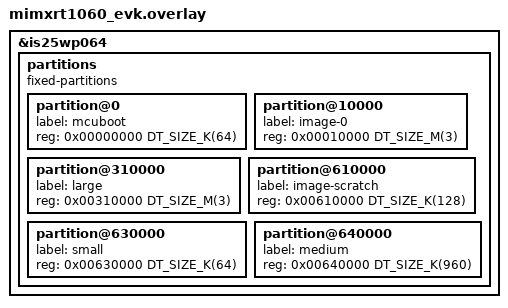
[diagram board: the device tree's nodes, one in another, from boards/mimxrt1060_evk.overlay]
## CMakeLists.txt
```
# SPDX-License-Identifier: Apache-2.0

cmake_minimum_required(VERSION 3.13.1)
find_package(Zephyr REQUIRED HINTS $ENV{ZEPHYR_BASE})
project(littlefs)

FILE(GLOB app_sources src/*.c)
# LittleFS opens files for RW by default if no flags given and crashes,
# instead of returning error when attempting to perform operation that
# a file has not been opened for.
target_compile_definitions(app PRIVATE
		BYPASS_FS_OPEN_FLAGS_LFS_ASSERT_CRASH
		BYPASS_FS_OPEN_FLAGS_LFS_RW_IS_DEFAULT
)
target_sources(app PRIVATE ${app_sources} ../common/test_fs_open_flags.c)
```

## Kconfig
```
# SPDX-License-Identifier: Apache-2.0
# Copyright (c) 2020 Nordic Semicondutor ASA

mainmenu "littlefs core functionality test"

source "Kconfig.zephyr"

config APP_TEST_CUSTOM
	bool "Select to test additional custom filesystem configurations"
```

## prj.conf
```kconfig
CONFIG_FILE_SYSTEM=y
CONFIG_FILE_SYSTEM_LITTLEFS=y

CONFIG_MAIN_STACK_SIZE=4096

# Performance tests need custom buffer allocation
CONFIG_MINIMAL_LIBC_MALLOC_ARENA_SIZE=8192

# FS abstraction layer is noisy so it's off.  Turn it on to see the
# littlefs configuration parameters.
#CONFIG_LOG=y
#CONFIG_FS_LOG_LEVEL_DBG=y

CONFIG_FLASH=y
CONFIG_FLASH_MAP=y
CONFIG_FLASH_PAGE_LAYOUT=y

CONFIG_ZTEST=y
CONFIG_ZTEST_STACKSIZE=4096
```

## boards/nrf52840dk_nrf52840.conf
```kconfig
#
# Copyright (c) 2019 Peter Bigot Consulting, LLC
# Copyright (c) 2019 Nordic Semiconductor ASA
#
# SPDX-License-Identifier: Apache-2.0
#

CONFIG_NORDIC_QSPI_NOR=y
CONFIG_NORDIC_QSPI_NOR_FLASH_LAYOUT_PAGE_SIZE=4096
```

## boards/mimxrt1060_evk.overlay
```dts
/*
 * Copyright (c) 2021 NXP
 *
 * SPDX-License-Identifier: Apache-2.0
 */

&is25wp064 {
	partitions {
		compatible = "fixed-partitions";
		#address-cells = <1>;
		#size-cells = <1>;

		partition@0 {
			label = "mcuboot";
			reg = <0x00000000 DT_SIZE_K(64)>;
		};
		partition@10000 {
			label = "image-0";
			reg = <0x00010000 DT_SIZE_M(3)>;
		};
		partition@310000 {
			label = "large";
			reg = <0x00310000 DT_SIZE_M(3)>;
		};
		partition@610000 {
			label = "image-scratch";
			reg = <0x00610000 DT_SIZE_K(128)>;
		};
		partition@630000 {
			label = "small";
			reg = <0x00630000 DT_SIZE_K(64)>;
		};
		partition@640000 {
			label = "medium";
			reg = <0x00640000 DT_SIZE_K(960)>;
		};
	};
};
```

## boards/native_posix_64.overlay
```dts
/*
 * Copyright (c) 2019 Jan Van Winkel <jan.van_winkel@dxplore.eu>
 *
 * SPDX-License-Identifier: Apache-2.0
 */

&flashcontroller0 {
	reg = <0x00000000 DT_SIZE_K(4096)>;
};

&flash0 {
	reg = <0x00000000 DT_SIZE_K(4096)>;
	partitions {
		compatible = "fixed-partitions";
		#address-cells = <1>;
		#size-cells = <1>;

		partition@0 {
			label = "small";
			reg = <0x00000000 0x00010000>;
		};
		partition@10000 {
			label = "medium";
			reg = <0x00010000 0x000F0000>;
		};
		partition@100000 {
			label = "large";
			reg = <0x00100000 0x00300000>;
		};
	};
};
```

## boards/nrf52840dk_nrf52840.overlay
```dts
/*
 * Copyright (c) 2019 Peter Bigot Consulting, LLC
 *
 * SPDX-License-Identifier: Apache-2.0
 */

&mx25r64 {
	partitions {
		compatible = "fixed-partitions";
		#address-cells = <1>;
		#size-cells = <1>;

 		partition@0 {
			label = "small";
			reg = <0x00000000 0x00010000>;
		};
		partition@10000 {
			label = "medium";
			reg = <0x00010000 0x000F0000>;
		};
		partition@100000 {
			label = "large";
			reg = <0x00100000 0x00300000>;
		};
	};
};
```

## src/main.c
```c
/*
 * Copyright (c) 2019 Peter Bigot Consulting, LLC
 *
 * SPDX-License-Identifier: Apache-2.0
 */

/* Tests of functions in testfs_util */

#include <string.h>
#include <ztest.h>
#include "testfs_tests.h"
#include "testfs_lfs.h"

void test_main(void)
{
	ztest_test_suite(littlefs_test,
			 ztest_unit_test(test_util_path_init_base),
			 ztest_unit_test(test_util_path_init_overrun),
			 ztest_unit_test(test_util_path_init_extended),
			 ztest_unit_test(test_util_path_extend),
			 ztest_unit_test(test_util_path_extend_up),
			 ztest_unit_test(test_util_path_extend_overrun),
			 ztest_unit_test(test_lfs_basic),
			 ztest_unit_test(test_lfs_dirops),
			 ztest_unit_test(test_lfs_perf),
			 ztest_unit_test(test_fs_open_flags_lfs),
			 ztest_unit_test(test_fs_mount_flags)
			 );
	ztest_run_test_suite(littlefs_test);
}
```

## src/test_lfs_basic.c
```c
/*
 * Copyright (c) 2019 Peter Bigot Consulting, LLC
 *
 * SPDX-License-Identifier: Apache-2.0
 */

/* Basic littlefs operations:
 * * create
 * * write
 * * stat
 * * read
 * * seek
 * * tell
 * * truncate
 * * unlink
 * * sync
 */

#include <string.h>
#include <ztest.h>
#include "testfs_tests.h"
#include "testfs_lfs.h"
#include <lfs.h>

#include <fs/littlefs.h>

#define HELLO "hello"
#define GOODBYE "goodbye"

static int mount(struct fs_mount_t *mp)
{
	TC_PRINT("mounting %s\n", mp->mnt_point);

	zassert_equal(fs_mount(mp), 0,
		      "mount failed");

	return TC_PASS;
}

static int clear_partition(struct fs_mount_t *mp)
{
	TC_PRINT("clearing partition %s\n", mp->mnt_point);

	zassert_equal(testfs_lfs_wipe_partition(mp),
		      TC_PASS,
		      "failed to wipe partition");

	return TC_PASS;
}

static int clean_statvfs(const struct fs_mount_t *mp)
{
	struct fs_statvfs stat;

	TC_PRINT("checking clean statvfs of %s\n", mp->mnt_point);

	zassert_equal(fs_statvfs(mp->mnt_point, &stat), 0,
		      "statvfs failed");

	TC_PRINT("%s: bsize %lu ; frsize %lu ; blocks %lu ; bfree %lu\n",
		 mp->mnt_point,
		 stat.f_bsize, stat.f_frsize, stat.f_blocks, stat.f_bfree);
	zassert_equal(stat.f_bsize, 16,
		      "bsize fail");
	zassert_equal(stat.f_frsize, 4096,
		      "frsize fail");
	zassert_equal(stat.f_blocks, 16,
		      "blocks fail");
	zassert_equal(stat.f_bfree, stat.f_blocks - 2U,
		      "bfree fail");

	return TC_PASS;
}

static int create_write_hello(const struct fs_mount_t *mp)
{
	struct testfs_path path;
	struct fs_file_t file;

	fs_file_t_init(&file);
	TC_PRINT("creating and writing file\n");

	zassert_equal(fs_open(&file,
			      testfs_path_init(&path, mp,
					       HELLO,
					       TESTFS_PATH_END),
			      FS_O_CREATE | FS_O_RDWR),
		      0,
		      "open hello failed");

	struct fs_dirent stat;

	zassert_equal(fs_stat(path.path, &stat),
		      0,
		      "stat new hello failed");

	zassert_equal(stat.type, FS_DIR_ENTRY_FILE,
		      "stat new hello not file");
	zassert_equal(strcmp(stat.name, HELLO), 0,
		      "stat new hello not hello");
	zassert_equal(stat.size, 0,
		      "stat new hello not empty");

	zassert_equal(testfs_write_incrementing(&file, 0, TESTFS_BUFFER_SIZE),
		      TESTFS_BUFFER_SIZE,
		      "write constant failed");

	zassert_equal(fs_stat(path.path, &stat),
		      0,
		      "stat written hello failed");

	zassert_equal(stat.type, FS_DIR_ENTRY_FILE,
		      "stat written hello not file");
	zassert_equal(strcmp(stat.name, HELLO), 0,
		      "stat written hello not hello");

	/* Anomalous behavior requiring upstream response */
	if (true) {
		/* VARIATION POINT: littlefs does not update the file size of
		 * an open file.  See upstream issue #250.
		 */
		zassert_equal(stat.size, 0,
			      "stat written hello bad size");
	}

	zassert_equal(fs_close(&file), 0,
		      "close hello failed");

	zassert_equal(fs_stat(path.path, &stat),
		      0,
		      "stat closed hello failed");

	zassert_equal(stat.type, FS_DIR_ENTRY_FILE,
		      "stat closed hello not file");
	zassert_equal(strcmp(stat.name, HELLO), 0,
		      "stat closed hello not hello");
	zassert_equal(stat.size, TESTFS_BUFFER_SIZE,
		      "stat closed hello badsize");

	return TC_PASS;
}

static int verify_hello(const struct fs_mount_t *mp)
{
	struct testfs_path path;
	struct fs_file_t file;

	fs_file_t_init(&file);
	TC_PRINT("opening and verifying file\n");

	zassert_equal(fs_open(&file,
			      testfs_path_init(&path, mp,
					       HELLO,
					       TESTFS_PATH_END),
			      FS_O_CREATE | FS_O_RDWR),
		      0,
		      "verify hello open failed");

	zassert_equal(fs_tell(&file), 0U,
		      "verify hello open tell failed");

	zassert_equal(testfs_verify_incrementing(&file, 0, TESTFS_BUFFER_SIZE),
		      TESTFS_BUFFER_SIZE,
		      "verify hello at start failed");

	zassert_equal(fs_tell(&file), TESTFS_BUFFER_SIZE,
		      "verify hello read tell failed");

	zassert_equal(fs_close(&file), 0,
		      "verify close hello failed");

	return TC_PASS;
}

static int seek_within_hello(const struct fs_mount_t *mp)
{
	struct testfs_path path;
	struct fs_file_t file;

	fs_file_t_init(&file);
	TC_PRINT("seek and tell in file\n");

	zassert_equal(fs_open(&file,
			      testfs_path_init(&path, mp,
					       HELLO,
					       TESTFS_PATH_END),
			      FS_O_CREATE | FS_O_RDWR),
		      0,
		      "verify hello open failed");

	zassert_equal(fs_tell(&file), 0U,
		      "verify hello open tell failed");

	struct fs_dirent stat;

	zassert_equal(fs_stat(path.path, &stat),
		      0,
		      "stat old hello failed");
	zassert_equal(stat.size, TESTFS_BUFFER_SIZE,
		      "stat old hello bad size");

	off_t pos = stat.size / 4;

	zassert_equal(fs_seek(&file, pos, FS_SEEK_SET),
		      0,
		      "verify hello seek near mid failed");

	zassert_equal(fs_tell(&file), pos,
		      "verify hello tell near mid failed");

	zassert_equal(testfs_verify_incrementing(&file, pos, TESTFS_BUFFER_SIZE),
		      TESTFS_BUFFER_SIZE - pos,
		      "verify hello at middle failed");

	zassert_equal(fs_tell(&file), stat.size,
		      "verify hello read middle tell failed");

	zassert_equal(fs_seek(&file, -stat.size, FS_SEEK_CUR),
		      0,
		      "verify hello seek back from cur failed");

	zassert_equal(fs_tell(&file), 0U,
		      "verify hello tell back from cur failed");

	zassert_equal(fs_seek(&file, -pos, FS_SEEK_END),
		      0,
		      "verify hello seek from end failed");

	zassert_equal(fs_tell(&file), stat.size - pos,
		      "verify hello tell from end failed");

	zassert_equal(testfs_verify_incrementing(&file, stat.size - pos,
						 TESTFS_BUFFER_SIZE),
		      pos,
		      "verify hello at post middle failed");

	zassert_equal(fs_close(&file), 0,
		      "verify close hello failed");

	return TC_PASS;
}

static int truncate_hello(const struct fs_mount_t *mp)
{
	struct testfs_path path;
	struct fs_file_t file;

	fs_file_t_init(&file);
	TC_PRINT("truncate in file\n");

	zassert_equal(fs_open(&file,
			      testfs_path_init(&path, mp,
					       HELLO,
					       TESTFS_PATH_END),
			      FS_O_CREATE | FS_O_RDWR),
		      0,
		      "verify hello open failed");

	struct fs_dirent stat;

	zassert_equal(fs_stat(path.path, &stat),
		      0,
		      "stat old hello failed");
	zassert_equal(stat.size, TESTFS_BUFFER_SIZE,
		      "stat old hello bad size");

	off_t pos = 3 * stat.size / 4;

	zassert_equal(fs_tell(&file), 0U,
		      "truncate initial tell failed");

	zassert_equal(fs_truncate(&file, pos),
		      0,
		      "truncate 3/4 failed");

	zassert_equal(fs_tell(&file), 0U,
		      "truncate post tell failed");

	zassert_equal(fs_stat(path.path, &stat),
		      0,
		      "stat open 3/4 failed");

	/* Anomalous behavior requiring upstream response */
	if (true) {
		/* VARIATION POINT: littlefs does not update the file size of
		 * an open file.  See upstream issue #250.
		 */
		zassert_equal(stat.size, TESTFS_BUFFER_SIZE,
			      "stat open 3/4 bad size");
	}

	zassert_equal(testfs_verify_incrementing(&file, 0, 64),
		      48,
		      "post truncate content unexpected");

	zassert_equal(fs_close(&file), 0,
		      "post truncate close failed");

	/* After close size is correct. */
	zassert_equal(fs_stat(path.path, &stat),
		      0,
		      "stat closed truncated failed");
	zassert_equal(stat.size, pos,
		      "stat closed truncated bad size");

	return TC_PASS;
}

static int unlink_hello(const struct fs_mount_t *mp)
{
	struct testfs_path path;

	TC_PRINT("unlink hello\n");

	testfs_path_init(&path, mp,
			 HELLO,
			 TESTFS_PATH_END);

	struct fs_dirent stat;

	zassert_equal(fs_stat(path.path, &stat),
		      0,
		      "stat existing hello failed");
	zassert_equal(fs_unlink(path.path),
		      0,
		      "unlink hello failed");
	zassert_equal(fs_stat(path.path, &stat),
		      -ENOENT,
		      "stat existing hello failed");

	return TC_PASS;
}

static int sync_goodbye(const struct fs_mount_t *mp)
{
	struct testfs_path path;
	struct fs_file_t file;

	fs_file_t_init(&file);
	TC_PRINT("sync goodbye\n");

	zassert_equal(fs_open(&file,
			      testfs_path_init(&path, mp,
					       GOODBYE,
					       TESTFS_PATH_END),
			      FS_O_CREATE | FS_O_RDWR),
		      0,
		      "sync goodbye failed");

	struct fs_dirent stat;

	zassert_equal(fs_stat(path.path, &stat),
		      0,
		      "stat existing hello failed");
	zassert_equal(stat.size, 0,
		      "stat new goodbye not empty");

	zassert_equal(testfs_write_incrementing(&file, 0, TESTFS_BUFFER_SIZE),
		      TESTFS_BUFFER_SIZE,
		      "write goodbye failed");

	zassert_equal(fs_tell(&file), TESTFS_BUFFER_SIZE,
		      "tell goodbye failed");

	if (true) {
		/* Upstream issue #250 */
		zassert_equal(stat.size, 0,
			      "stat new goodbye not empty");
	}

	zassert_equal(fs_sync(&file), 0,
		      "sync goodbye failed");

	zassert_equal(fs_tell(&file), TESTFS_BUFFER_SIZE,
		      "tell synced moved");

	zassert_equal(fs_stat(path.path, &stat),
		      0,
		      "stat existing hello failed");
	printk("sync size %u\n", (uint32_t)stat.size);

	zassert_equal(stat.size, TESTFS_BUFFER_SIZE,
		      "stat synced goodbye not correct");

	zassert_equal(fs_close(&file), 0,
		      "post sync close failed");

	/* After close size is correct. */
	zassert_equal(fs_stat(path.path, &stat),
		      0,
		      "stat sync failed");
	zassert_equal(stat.size, TESTFS_BUFFER_SIZE,
		      "stat sync bad size");

	return TC_PASS;
}

static int verify_goodbye(const struct fs_mount_t *mp)
{
	struct testfs_path path;
	struct fs_file_t file;

	fs_file_t_init(&file);
	TC_PRINT("verify goodbye\n");

	zassert_equal(fs_open(&file,
			      testfs_path_init(&path, mp,
					       GOODBYE,
					       TESTFS_PATH_END),
			      FS_O_CREATE | FS_O_RDWR),
		      0,
		      "verify goodbye failed");

	zassert_equal(testfs_verify_incrementing(&file, 0, TESTFS_BUFFER_SIZE),
		      TESTFS_BUFFER_SIZE,
		      "write goodbye failed");

	zassert_equal(fs_close(&file), 0,
		      "post sync close failed");

	return TC_PASS;
}

static int check_medium(void)
{
	struct fs_mount_t *mp = &testfs_medium_mnt;
	struct fs_statvfs stat;

	zassert_equal(clear_partition(mp), TC_PASS,
		      "clear partition failed");

	zassert_equal(fs_mount(mp), 0,
		      "medium mount failed");

	zassert_equal(fs_statvfs(mp->mnt_point, &stat), 0,
		      "statvfs failed");

	TC_PRINT("%s: bsize %lu ; frsize %lu ; blocks %lu ; bfree %lu\n",
		 mp->mnt_point,
		 stat.f_bsize, stat.f_frsize, stat.f_blocks, stat.f_bfree);
	zassert_equal(stat.f_bsize, MEDIUM_IO_SIZE,
		      "bsize fail");
	zassert_equal(stat.f_frsize, 4096,
		      "frsize fail");
	zassert_equal(stat.f_blocks, 240,
		      "blocks fail");
	zassert_equal(stat.f_bfree, stat.f_blocks - 2U,
		      "bfree fail");

	zassert_equal(fs_unmount(mp), 0,
		      "medium unmount failed");

	return TC_PASS;
}

static int check_large(void)
{
	struct fs_mount_t *mp = &testfs_large_mnt;
	struct fs_statvfs stat;

	zassert_equal(clear_partition(mp), TC_PASS,
		      "clear partition failed");

	zassert_equal(fs_mount(mp), 0,
		      "large mount failed");

	zassert_equal(fs_statvfs(mp->mnt_point, &stat), 0,
		      "statvfs failed");

	TC_PRINT("%s: bsize %lu ; frsize %lu ; blocks %lu ; bfree %lu\n",
		 mp->mnt_point,
		 stat.f_bsize, stat.f_frsize, stat.f_blocks, stat.f_bfree);
	zassert_equal(stat.f_bsize, LARGE_IO_SIZE,
		      "bsize fail");
	zassert_equal(stat.f_frsize, 32768,
		      "frsize fail");
	zassert_equal(stat.f_blocks, 96,
		      "blocks fail");
	zassert_equal(stat.f_bfree, stat.f_blocks - 2U,
		      "bfree fail");

	zassert_equal(fs_unmount(mp), 0,
		      "large unmount failed");

	return TC_PASS;
}

static int num_files(struct fs_mount_t *mp)
{
	struct testfs_path path;
	char name[2] = { 0 };
	const char *pstr;
	struct fs_file_t files[CONFIG_FS_LITTLEFS_NUM_FILES];
	size_t fi = 0;
	int rc;

	memset(files, 0, sizeof(files));

	TC_PRINT("CONFIG_FS_LITTLEFS_NUM_FILES=%u\n", CONFIG_FS_LITTLEFS_NUM_FILES);
	while (fi < ARRAY_SIZE(files)) {
		struct fs_file_t *const file = &files[fi];

		name[0] = 'A' + fi;
		pstr = testfs_path_init(&path, mp,
					name,
					TESTFS_PATH_END);

		TC_PRINT("opening %s\n", pstr);
		rc = fs_open(file, pstr, FS_O_CREATE | FS_O_RDWR);
		zassert_equal(rc, 0, "open %s failed: %d", pstr, rc);

		rc = testfs_write_incrementing(file, 0, TESTFS_BUFFER_SIZE);
		zassert_equal(rc, TESTFS_BUFFER_SIZE, "write %s failed: %d", pstr, rc);

		++fi;
	}

	while (fi-- != 0)  {
		struct fs_file_t *const file = &files[fi];

		name[0] = 'A' + fi;
		pstr = testfs_path_init(&path, mp,
					name,
					TESTFS_PATH_END);

		TC_PRINT("Close and unlink %s\n", pstr);

		rc = fs_close(file);
		zassert_equal(rc, 0, "close %s failed: %d", pstr, rc);

		rc = fs_unlink(pstr);
		zassert_equal(rc, 0, "unlink %s failed: %d", pstr, rc);
	}

	return TC_PASS;
}

static int num_dirs(struct fs_mount_t *mp)
{
	struct testfs_path path;
	char name[3] = "Dx";
	const char *pstr;
	struct fs_dir_t dirs[CONFIG_FS_LITTLEFS_NUM_DIRS];
	size_t di = 0;
	int rc;

	memset(dirs, 0, sizeof(dirs));

	TC_PRINT("CONFIG_FS_LITTLEFS_NUM_DIRS=%u\n", CONFIG_FS_LITTLEFS_NUM_DIRS);
	while (di < ARRAY_SIZE(dirs)) {
		struct fs_dir_t *const dir = &dirs[di];

		name[1] = 'A' + di;
		pstr = testfs_path_init(&path, mp,
					name,
					TESTFS_PATH_END);

		TC_PRINT("making and opening directory %s\n", pstr);
		rc = fs_mkdir(pstr);
		zassert_equal(rc, 0, "mkdir %s failed: %d", pstr, rc);

		rc = fs_opendir(dir, pstr);
		zassert_equal(rc, 0, "opendir %s failed: %d", name, rc);

		++di;
	}

	while (di-- != 0)  {
		struct fs_dir_t *const dir = &dirs[di];

		name[1] = 'A' + di;
		pstr = testfs_path_init(&path, mp,
					name,
					TESTFS_PATH_END);

		TC_PRINT("Close and rmdir %s\n", pstr);

		rc = fs_closedir(dir);
		zassert_equal(rc, 0, "closedir %s failed: %d", name, rc);

		rc = fs_unlink(pstr);
		zassert_equal(rc, 0, "unlink %s failed: %d", name, rc);
	}

	return TC_PASS;
}

void test_lfs_basic(void)
{
	struct fs_mount_t *mp = &testfs_small_mnt;

	zassert_equal(clear_partition(mp), TC_PASS,
		      "clear partition failed");

	zassert_equal(mount(mp), TC_PASS,
		      "clean mount failed");

	zassert_equal(clean_statvfs(mp), TC_PASS,
		      "clean statvfs failed");

	zassert_equal(create_write_hello(mp), TC_PASS,
		      "write hello failed");

	zassert_equal(verify_hello(mp), TC_PASS,
		      "verify hello failed");

	zassert_equal(seek_within_hello(mp), TC_PASS,
		      "seek within hello failed");

	zassert_equal(truncate_hello(mp), TC_PASS,
		      "truncate hello failed");

	zassert_equal(unlink_hello(mp), TC_PASS,
		      "unlink hello failed");

	zassert_equal(sync_goodbye(mp), TC_PASS,
		      "sync goodbye failed");

	zassert_equal(num_files(mp), TC_PASS,
		      "num_files failed");

	zassert_equal(num_dirs(mp), TC_PASS,
		      "num_dirs failed");

	TC_PRINT("unmounting %s\n", mp->mnt_point);
	zassert_equal(fs_unmount(mp), 0,
		      "unmount small failed");

	k_sleep(K_MSEC(100));   /* flush log messages */
	TC_PRINT("checking double unmount diagnoses\n");
	zassert_equal(fs_unmount(mp), -EINVAL,
		      "unmount unmounted failed");

	zassert_equal(mount(mp), TC_PASS,
		      "remount failed");

	zassert_equal(verify_goodbye(mp), TC_PASS,
		      "verify goodbye failed");

	zassert_equal(fs_unmount(mp), 0,
		      "unmount2 small failed");

	if (IS_ENABLED(CONFIG_APP_TEST_CUSTOM)) {
		zassert_equal(check_medium(), TC_PASS,
			      "check medium failed");

		zassert_equal(check_large(), TC_PASS,
			      "check large failed");
	}
}
```

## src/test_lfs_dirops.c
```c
/*
 * Copyright (c) 2019 Peter Bigot Consulting, LLC
 *
 * SPDX-License-Identifier: Apache-2.0
 */

/* Director littlefs operations:
 * * mkdir
 * * opendir
 * * readdir
 * * closedir
 * * rename
 */

#include <string.h>
#include <ztest.h>
#include "testfs_tests.h"
#include "testfs_lfs.h"
#include <lfs.h>

#include <fs/littlefs.h>

static struct testfs_bcmd test_hierarchy[] = {
	TESTFS_BCMD_FILE("f1", 1, 1),
	TESTFS_BCMD_FILE("f2", 2, 100),
	TESTFS_BCMD_ENTER_DIR("d1"),
	TESTFS_BCMD_FILE("d1f1", 11, 23),
	TESTFS_BCMD_FILE("d1f2", 12, 612),
	TESTFS_BCMD_EXIT_DIR(),
	TESTFS_BCMD_FILE("f3", 3, 10000),
	TESTFS_BCMD_END(),
};

static int clean_mount(struct fs_mount_t *mp)
{
	TC_PRINT("checking clean mount\n");

	zassert_equal(testfs_lfs_wipe_partition(mp),
		      TC_PASS,
		      "failed to wipe partition");
	zassert_equal(fs_mount(mp), 0,
		      "mount small failed");

	return TC_PASS;
}

static int check_mkdir(struct fs_mount_t *mp)
{
	struct testfs_path dpath;

	TC_PRINT("checking dir create unlink\n");
	zassert_equal(testfs_path_init(&dpath, mp,
				       "dir",
				       TESTFS_PATH_END),
		      dpath.path,
		      "root init failed");

	zassert_equal(fs_mkdir(dpath.path),
		      0,
		      "mkdir failed");

	struct fs_file_t file;
	struct testfs_path fpath;

	fs_file_t_init(&file);
	zassert_equal(fs_open(&file,
			      testfs_path_extend(testfs_path_copy(&fpath,
								  &dpath),
						 "file",
						 TESTFS_PATH_END),
			      FS_O_CREATE | FS_O_RDWR),
		      0,
		      "creat in dir failed");
	zassert_equal(fs_close(&file), 0,
		      "close file failed");

	struct fs_dirent stat;

	zassert_equal(fs_stat(fpath.path, &stat), 0,
		      "stat file failed");

	zassert_equal(fs_unlink(dpath.path),
		      -ENOTEMPTY,
		      "unlink bad failure");

	zassert_equal(fs_unlink(fpath.path),
		      0,
		      "unlink file failed");

	zassert_equal(fs_unlink(dpath.path),
		      0,
		      "unlink dir failed");

	return TC_PASS;
}

static int build_layout(struct fs_mount_t *mp,
			const struct testfs_bcmd *cp)
{
	struct testfs_path path;
	struct fs_statvfs stat;

	TC_PRINT("building layout on %s\n", mp->mnt_point);

	zassert_equal(fs_statvfs(mp->mnt_point, &stat), 0,
		      "statvfs failed");

	TC_PRINT("before: bsize %lu ; frsize %lu ; blocks %lu ; bfree %lu\n",
		 stat.f_bsize, stat.f_frsize, stat.f_blocks, stat.f_bfree);

	zassert_equal(testfs_path_init(&path, mp, TESTFS_PATH_END),
		      path.path,
		      "root init failed");

	zassert_equal(testfs_build(&path, cp),
		      0,
		      "build_layout failed");

	zassert_equal(fs_statvfs(mp->mnt_point, &stat), 0,
		      "statvfs failed");

	TC_PRINT("after: bsize %lu ; frsize %lu ; blocks %lu ; bfree %lu\n",
		 stat.f_bsize, stat.f_frsize, stat.f_blocks, stat.f_bfree);

	return TC_PASS;
}

static int check_layout(struct fs_mount_t *mp,
			struct testfs_bcmd *layout)
{
	struct testfs_path path;
	struct testfs_bcmd *end_layout = testfs_bcmd_end(layout);

	TC_PRINT("checking layout\n");

	zassert_equal(testfs_path_init(&path, mp, TESTFS_PATH_END),
		      path.path,
		      "root init failed");

	int rc = testfs_bcmd_verify_layout(&path, layout, end_layout);

	zassert_true(rc >= 0, "layout check failed");

	zassert_equal(rc, 0,
		      "layout found foreign");

	struct testfs_bcmd *cp = layout;

	while (!TESTFS_BCMD_IS_END(cp)) {
		if (cp->name != NULL) {
			TC_PRINT("verifying %s%s %u\n",
				 cp->name,
				 (cp->type == FS_DIR_ENTRY_DIR) ? "/" : "",
				 cp->size);
			zassert_true(cp->matched,
				     "Unmatched layout entry");
		}
		++cp;
	}

	return TC_PASS;
}

static int check_rename(struct fs_mount_t *mp)
{
	struct testfs_path root;
	struct testfs_path from_path;
	const char *from = from_path.path;
	struct testfs_path to_path;
	const char *to = to_path.path;
	struct fs_dirent stat;
	struct testfs_bcmd from_bcmd[] = {
		TESTFS_BCMD_FILE("f1f", 1, 8),  /* from f1f to f1t */
		TESTFS_BCMD_FILE("f2f", 2, 8),  /* from f2f to f2t */
		TESTFS_BCMD_FILE("f2t", 3, 8),  /* target for f2f clobber, replaced */
		TESTFS_BCMD_FILE("f3f", 4, 8),  /* from f3f to d1f/d1f2t */
		TESTFS_BCMD_FILE("f4f", 5, 8),  /* from f4f to d2t, reject */
		TESTFS_BCMD_ENTER_DIR("d1f"),   /* from d1f to d1t */
		TESTFS_BCMD_FILE("d1f1", 5, 16),
		TESTFS_BCMD_EXIT_DIR(),
		TESTFS_BCMD_ENTER_DIR("d2t"),  /* target for d1f, unchanged */
		TESTFS_BCMD_FILE("d2f1", 6, 16),
		TESTFS_BCMD_EXIT_DIR(),
		TESTFS_BCMD_END(),
	};
	struct testfs_bcmd *from_end_bcmd = testfs_bcmd_end(from_bcmd);
	struct testfs_bcmd to_bcmd[] = {
		TESTFS_BCMD_FILE("f1t", 1, 8),          /* from f1f to f1t */
		TESTFS_BCMD_FILE("f2t", 2, 8),          /* from f2f to f2t */
		TESTFS_BCMD_FILE("f4f", 5, 8),          /* from f4f to d2t, reject */
		TESTFS_BCMD_ENTER_DIR("d1t"),           /* from d1f to d1t */
		TESTFS_BCMD_FILE("d1f1", 5, 16),
		TESTFS_BCMD_FILE("d1f2t", 4, 8),        /* from f3f to d1f/d1f2t */
		TESTFS_BCMD_EXIT_DIR(),
		TESTFS_BCMD_ENTER_DIR("d2t"),           /* target for d1f, unchanged */
		TESTFS_BCMD_FILE("d2f1", 6, 16),
		TESTFS_BCMD_EXIT_DIR(),
		TESTFS_BCMD_END(),
	};
	struct testfs_bcmd *to_end_bcmd = testfs_bcmd_end(to_bcmd);

	zassert_equal(testfs_path_init(&root, mp,
				       "rename",
				       TESTFS_PATH_END),
		      root.path,
		      "root init failed");

	zassert_equal(fs_mkdir(root.path),
		      0,
		      "rename mkdir failed");
	zassert_equal(testfs_build(&root, from_bcmd),
		      0,
		      "rename build failed");

	zassert_equal(testfs_bcmd_verify_layout(&root, from_bcmd, from_end_bcmd),
		      0,
		      "layout check failed");

	testfs_path_extend(testfs_path_copy(&from_path, &root),
			   "nofile",
			   TESTFS_PATH_END);
	testfs_path_extend(testfs_path_copy(&to_path, &root),
			   "f1t",
			   TESTFS_PATH_END);
	TC_PRINT("%s => %s -ENOENT\n", from, to);
	zassert_equal(fs_rename(from, to),
		      -ENOENT,
		      "rename noent failed");

	/* f1f => f1t : ok */
	testfs_path_extend(testfs_path_copy(&from_path, &root),
			   "f1f",
			   TESTFS_PATH_END);
	TC_PRINT("%s => %s ok\n", from, to);
	zassert_equal(fs_rename(from, to),
		      0,
		      "rename noent failed");

	/* f2f => f2t : clobbers */
	testfs_path_extend(testfs_path_copy(&from_path, &root),
			   "f2f",
			   TESTFS_PATH_END);
	testfs_path_extend(testfs_path_copy(&to_path, &root),
			   "f2t",
			   TESTFS_PATH_END);
	TC_PRINT("%s => %s clobber ok\n", from, to);
	zassert_equal(fs_rename(from, to),
		      0,
		      "rename clobber failed");
	zassert_equal(fs_stat(from, &stat),
		      -ENOENT,
		      "rename clobber left from");

	/* f3f => d1f/d1f2t : moves */
	testfs_path_extend(testfs_path_copy(&from_path, &root),
			   "f3f",
			   TESTFS_PATH_END);
	testfs_path_extend(testfs_path_copy(&to_path, &root),
			   "d1f", "d1f2t",
			   TESTFS_PATH_END);
	TC_PRINT("%s => %s move ok\n", from, to);
	zassert_equal(fs_rename(from, to),
		      0,
		      "rename to subdir failed");
	zassert_equal(fs_stat(from, &stat),
		      -ENOENT,
		      "rename to subdir left from");

	/* d1f => d2t : reject */
	testfs_path_extend(testfs_path_copy(&from_path, &root),
			   "d1f",
			   TESTFS_PATH_END);
	testfs_path_extend(testfs_path_copy(&to_path, &root),
			   "d2t",
			   TESTFS_PATH_END);
	TC_PRINT("%s => %s -ENOTEMPTY\n", from, to);
	zassert_equal(fs_rename(from, to),
		      -ENOTEMPTY,
		      "rename to existing dir failed");

	/* d1f => d1t : rename */
	testfs_path_extend(testfs_path_copy(&from_path, &root),
			   "d1f",
			   TESTFS_PATH_END);
	testfs_path_extend(testfs_path_copy(&to_path, &root),
			   "d1t",
			   TESTFS_PATH_END);
	TC_PRINT("%s => %s ok\n", from, to);
	zassert_equal(fs_rename(from, to),
		      0,
		      "rename to new dir failed");
	zassert_equal(fs_stat(from, &stat),
		      -ENOENT,
		      "rename to new dir left from");

	zassert_equal(testfs_bcmd_verify_layout(&root, to_bcmd, to_end_bcmd),
		      0,
		      "layout verification failed");

	struct testfs_bcmd *cp = to_bcmd;

	while (cp != to_end_bcmd) {
		if (cp->name) {
			zassert_true(cp->matched, "foriegn file retained");
		}
		++cp;
	}

	return TC_PASS;
}

void test_lfs_dirops(void)
{
	struct fs_mount_t *mp = &testfs_small_mnt;

	zassert_equal(clean_mount(mp), TC_PASS,
		      "clean mount failed");

	zassert_equal(check_mkdir(mp), TC_PASS,
		      "check mkdir failed");

	k_sleep(K_MSEC(100));   /* flush log messages */
	zassert_equal(build_layout(mp, test_hierarchy), TC_PASS,
		      "build test hierarchy failed");

	k_sleep(K_MSEC(100));   /* flush log messages */
	zassert_equal(check_layout(mp, test_hierarchy), TC_PASS,
		      "check test hierarchy failed");

	k_sleep(K_MSEC(100));   /* flush log messages */
	zassert_equal(check_rename(mp), TC_PASS,
		      "check rename failed");

	k_sleep(K_MSEC(100));   /* flush log messages */
	zassert_equal(fs_unmount(mp), 0,
		      "unmount small failed");
}
```

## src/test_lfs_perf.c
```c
/*
 * Copyright (c) 2019 Peter Bigot Consulting, LLC
 *
 * SPDX-License-Identifier: Apache-2.0
 */

/* littlefs performance testing */

#include <string.h>
#include <stdlib.h>
#include <kernel.h>
#include <ztest.h>
#include "testfs_tests.h"
#include "testfs_lfs.h"
#include <lfs.h>

#include <fs/littlefs.h>

#define HELLO "hello"
#define GOODBYE "goodbye"

static int write_read(const char *tag,
		      struct fs_mount_t *mp,
		      size_t buf_size,
		      size_t nbuf)
{
	const struct lfs_config *lcp = &((const struct fs_littlefs *)mp->fs_data)->cfg;
	struct testfs_path path;
	struct fs_statvfs vfs;
	struct fs_dirent stat;
	struct fs_file_t file;
	size_t total = nbuf * buf_size;
	uint32_t t0;
	uint32_t t1;
	uint8_t *buf;
	int rc;
	int rv = TC_FAIL;

	fs_file_t_init(&file);
	TC_PRINT("clearing %s for %s write/read test\n",
		 mp->mnt_point, tag);
	if (testfs_lfs_wipe_partition(mp) != TC_PASS) {
		return TC_FAIL;
	}

	rc = fs_mount(mp);
	if (rc != 0) {
		TC_PRINT("Mount %s failed: %d\n", mp->mnt_point, rc);
		return TC_FAIL;
	}

	rc = fs_statvfs(mp->mnt_point, &vfs);
	if (rc != 0) {
		TC_PRINT("statvfs %s failed: %d\n", mp->mnt_point, rc);
		goto out_mnt;
	}

	TC_PRINT("%s: bsize %lu ; frsize %lu ; blocks %lu ; bfree %lu\n",
		 mp->mnt_point,
		 vfs.f_bsize, vfs.f_frsize, vfs.f_blocks, vfs.f_bfree);
	TC_PRINT("read_size %u ; prog_size %u ; cache_size %u ; lookahead_size %u\n",
		 lcp->read_size, lcp->prog_size, lcp->cache_size, lcp->lookahead_size);

	testfs_path_init(&path, mp,
			 "data",
			 TESTFS_PATH_END);

	buf = calloc(buf_size, sizeof(uint8_t));
	if (buf == NULL) {
		TC_PRINT("Failed to allocate %zu-byte buffer\n", buf_size);
		goto out_mnt;
	}

	for (size_t i = 0; i < buf_size; ++i) {
		buf[i] = i;
	}

	TC_PRINT("creating and writing %zu %zu-byte blocks\n",
		 nbuf, buf_size);

	rc = fs_open(&file, path.path, FS_O_CREATE | FS_O_RDWR);
	if (rc != 0) {
		TC_PRINT("Failed to open %s for write: %d\n", path.path, rc);
		goto out_buf;
	}

	t0 = k_uptime_get_32();
	for (size_t i = 0; i < nbuf; ++i) {
		rc = fs_write(&file, buf, buf_size);
		if (buf_size != rc) {
			TC_PRINT("Failed to write buf %zu: %d\n", i, rc);
			goto out_file;
		}
	}
	t1 = k_uptime_get_32();

	if (t1 == t0) {
		t1++;
	}

	(void)fs_close(&file);

	rc = fs_stat(path.path, &stat);
	if (rc != 0) {
		TC_PRINT("Failed to stat %s: %d\n", path.path, rc);
		goto out_buf;
	}

	if (stat.size != total) {
		TC_PRINT("File size %zu not %zu\n", stat.size, total);
		goto out_buf;
	}

	TC_PRINT("%s write %zu * %zu = %zu bytes in %u ms: "
		 "%u By/s, %u KiBy/s\n",
		 tag, nbuf, buf_size, total, (t1 - t0),
		 (uint32_t)(total * 1000U / (t1 - t0)),
		 (uint32_t)(total * 1000U / (t1 - t0) / 1024U));

	rc = fs_open(&file, path.path, FS_O_CREATE | FS_O_RDWR);
	if (rc != 0) {
		TC_PRINT("Failed to open %s for write: %d\n", path.path, rc);
		goto out_buf;
	}

	t0 = k_uptime_get_32();
	for (size_t i = 0; i < nbuf; ++i) {
		rc = fs_read(&file, buf, buf_size);
		if (buf_size != rc) {
			TC_PRINT("Failed to read buf %zu: %d\n", i, rc);
			goto out_file;
		}
	}
	t1 = k_uptime_get_32();

	if (t1 == t0) {
		t1++;
	}

	TC_PRINT("%s read %zu * %zu = %zu bytes in %u ms: "
		 "%u By/s, %u KiBy/s\n",
		 tag, nbuf, buf_size, total, (t1 - t0),
		 (uint32_t)(total * 1000U / (t1 - t0)),
		 (uint32_t)(total * 1000U / (t1 - t0) / 1024U));

	rv = TC_PASS;

out_file:
	(void)fs_close(&file);

out_buf:
	free(buf);

out_mnt:
	(void)fs_unmount(mp);

	return rv;
}

static int custom_write_test(const char *tag,
			     const struct fs_mount_t *mp,
			     const struct lfs_config *cfgp,
			     size_t buf_size,
			     size_t nbuf)
{
	struct fs_littlefs data = {
		.cfg = *cfgp,
	};
	struct fs_mount_t lfs_mnt = {
		.type = FS_LITTLEFS,
		.fs_data = &data,
		.storage_dev = mp->storage_dev,
		.mnt_point = mp->mnt_point,
	};
	struct lfs_config *lcp = &data.cfg;
	int rv = TC_FAIL;

	if (lcp->cache_size == 0) {
		lcp->cache_size = CONFIG_FS_LITTLEFS_CACHE_SIZE;
	}
	if (lcp->lookahead_size == 0) {
		lcp->lookahead_size = CONFIG_FS_LITTLEFS_LOOKAHEAD_SIZE;
	}

	lcp->read_buffer = malloc(lcp->cache_size);
	lcp->prog_buffer = malloc(lcp->cache_size);
	lcp->lookahead_buffer = malloc(lcp->lookahead_size);

	TC_PRINT("bufs %p %p %p\n", lcp->read_buffer, lcp->prog_buffer, lcp->lookahead_buffer);

	if ((lcp->read_buffer == NULL)
	    || (lcp->prog_buffer == NULL)
	    || (lcp->lookahead_buffer == NULL)) {
		TC_PRINT("%s buffer allocation failed\n", tag);
		goto out_free;
	}

	rv = write_read(tag, &lfs_mnt, buf_size, nbuf);

out_free:
	if (lcp->read_buffer) {
		free(lcp->read_buffer);
	}
	if (lcp->prog_buffer) {
		free(lcp->prog_buffer);
	}
	if (lcp->lookahead_buffer) {
		free(lcp->lookahead_buffer);
	}

	return rv;
}

static int small_8_1K_cust(void)
{
	struct lfs_config cfg = {
		.read_size = LARGE_IO_SIZE,
		.prog_size = LARGE_IO_SIZE,
		.cache_size = LARGE_CACHE_SIZE,
		.lookahead_size = LARGE_LOOKAHEAD_SIZE
	};

	return custom_write_test("small 8x1K bigfile", &testfs_small_mnt, &cfg, 1024, 8);
}

void test_lfs_perf(void)
{
	k_sleep(K_MSEC(100));   /* flush log messages */
	zassert_equal(write_read("small 8x1K dflt",
				 &testfs_small_mnt,
				 1024, 8),
		      TC_PASS,
		      "failed");

	if (IS_ENABLED(CONFIG_APP_TEST_CUSTOM)) {
		k_sleep(K_MSEC(100));   /* flush log messages */
		zassert_equal(small_8_1K_cust(), TC_PASS,
			      "failed");

		k_sleep(K_MSEC(100));   /* flush log messages */
		zassert_equal(write_read("medium 32x2K dflt",
					 &testfs_medium_mnt,
					 2048, 32),
			      TC_PASS,
			      "failed");

		k_sleep(K_MSEC(100));   /* flush log messages */
		zassert_equal(write_read("large 64x4K dflt",
					 &testfs_large_mnt,
					 4096, 64),
			      TC_PASS,
			      "failed");
	}
}
```

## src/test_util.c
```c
/*
 * Copyright (c) 2019 Peter Bigot Consulting, LLC
 *
 * SPDX-License-Identifier: Apache-2.0
 */

/* Tests of functions in testfs_util */

#include <string.h>
#include <ztest.h>
#include "testfs_tests.h"
#include "testfs_util.h"

#define MNT "/mnt"
#define ELT1 "a"
#define ELT2 "b"

static struct testfs_path path;
static const struct fs_mount_t mnt = {
	.mnt_point = MNT,
};

static inline struct testfs_path *reset_path()
{
	testfs_path_init(&path, &mnt, TESTFS_PATH_END);
	return &path;
}

void test_util_path_init_base(void)
{
	zassert_equal(testfs_path_init(&path, NULL, TESTFS_PATH_END),
		      path.path,
		      "bad root init return");
	zassert_equal(strcmp(path.path, "/"), 0, "bad root init path");

	zassert_equal(testfs_path_init(&path, &mnt, TESTFS_PATH_END),
		      path.path,
		      "bad mnt init return");
	zassert_equal(strcmp(path.path, mnt.mnt_point), 0, "bad mnt init path");

	if (IS_ENABLED(CONFIG_DEBUG)) {
		struct fs_mount_t invalid = {
			.mnt_point = "relative",
		};

		/* Apparently no way to verify this without panic. */
		testfs_path_init(&path, &invalid, TESTFS_PATH_END);
	}
}

void test_util_path_init_overrun(void)
{
	char overrun[TESTFS_PATH_MAX + 2] = "/";
	size_t overrun_max = sizeof(overrun) - 1;
	size_t path_max = sizeof(path.path) - 1;
	struct fs_mount_t overrun_mnt = {
		.mnt_point = overrun,
	};

	zassert_true(path_max < overrun_max,
		     "path length requirements unmet");

	memset(overrun + 1, 'A', overrun_max - 1);

	zassert_equal(testfs_path_init(&path, &overrun_mnt, TESTFS_PATH_END),
		      path.path,
		      "bad overrun init return");
	zassert_true(strcmp(path.path, overrun) < 0,
		     "bad overrun init");
	zassert_equal(strncmp(path.path, overrun, path_max),
		      0,
		      "bad overrun path");
	zassert_equal(path.path[path_max], '\0',
		      "missing overrun EOS");
}

void test_util_path_init_extended(void)
{
	zassert_equal(strcmp(testfs_path_init(&path, &mnt,
					      ELT1,
					      TESTFS_PATH_END),
			     MNT "/" ELT1),
		      0,
		      "bad mnt init elt1");

	zassert_equal(strcmp(testfs_path_init(&path, &mnt,
					      ELT1,
					      ELT2,
					      TESTFS_PATH_END),
			     MNT "/" ELT1 "/" ELT2),
		      0,
		      "bad mnt init elt1 elt2");
}

void test_util_path_extend(void)
{
	zassert_equal(strcmp(testfs_path_extend(reset_path(),
						TESTFS_PATH_END),
			     MNT),
		      0,
		      "empty extend failed");

	zassert_equal(strcmp(testfs_path_extend(reset_path(),
						ELT2,
						TESTFS_PATH_END),
			     MNT "/" ELT2),
		      0,
		      "elt extend failed");

	zassert_equal(strcmp(testfs_path_extend(reset_path(),
						ELT1,
						ELT2,
						TESTFS_PATH_END),
			     MNT "/" ELT1 "/" ELT2),
		      0,
		      "elt1 elt2 extend failed");
}

void test_util_path_extend_up(void)
{
	zassert_equal(strcmp(testfs_path_extend(reset_path(),
						ELT2,
						"..",
						ELT1,
						TESTFS_PATH_END),
			     MNT "/" ELT1),
		      0,
		      "elt elt2, up, elt1 failed");

	zassert_equal(strcmp(testfs_path_extend(reset_path(),
						"..",
						TESTFS_PATH_END),
			     "/"),
		      0,
		      "up strip mnt failed");

	zassert_equal(strcmp(testfs_path_extend(reset_path(),
						"..",
						"..",
						TESTFS_PATH_END),
			     "/"),
		      0,
		      "up from root failed");
}

void test_util_path_extend_overrun(void)
{
	char long_elt[TESTFS_PATH_MAX];

	memset(long_elt, 'a', sizeof(long_elt) - 1);
	long_elt[sizeof(long_elt) - 1] = '\0';

	zassert_equal(strcmp(testfs_path_extend(reset_path(),
						long_elt,
						ELT1,
						TESTFS_PATH_END),
			     MNT),
		      0,
		      "stop at overrun failed");
}
```

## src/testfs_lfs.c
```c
/*
 * Copyright (c) 2019 Peter Bigot Consulting, LLC
 *
 * SPDX-License-Identifier: Apache-2.0
 */

#include <ztest.h>
#include <fs/littlefs.h>
#include <storage/flash_map.h>
#include "testfs_lfs.h"

FS_LITTLEFS_DECLARE_DEFAULT_CONFIG(small);
struct fs_mount_t testfs_small_mnt = {
	.type = FS_LITTLEFS,
	.fs_data = &small,
	.storage_dev = (void *)FLASH_AREA_ID(small),
	.mnt_point = TESTFS_MNT_POINT_SMALL,
};

#if CONFIG_APP_TEST_CUSTOM
FS_LITTLEFS_DECLARE_CUSTOM_CONFIG(medium, MEDIUM_IO_SIZE, MEDIUM_IO_SIZE,
				  MEDIUM_CACHE_SIZE, MEDIUM_LOOKAHEAD_SIZE);
struct fs_mount_t testfs_medium_mnt = {
	.type = FS_LITTLEFS,
	.fs_data = &medium,
	.storage_dev = (void *)FLASH_AREA_ID(medium),
	.mnt_point = TESTFS_MNT_POINT_MEDIUM,
};

static uint8_t large_read_buffer[LARGE_CACHE_SIZE];
static uint8_t large_prog_buffer[LARGE_CACHE_SIZE];
static uint32_t large_lookahead_buffer[LARGE_LOOKAHEAD_SIZE / 4U];
static struct fs_littlefs large = {
	.cfg = {
		.read_size = LARGE_IO_SIZE,
		.prog_size = LARGE_IO_SIZE,
		.cache_size = LARGE_CACHE_SIZE,
		.lookahead_size = LARGE_LOOKAHEAD_SIZE,
		.block_size = 32768, /* increase erase size */
		.read_buffer = large_read_buffer,
		.prog_buffer = large_prog_buffer,
		.lookahead_buffer = large_lookahead_buffer,
	},
};
struct fs_mount_t testfs_large_mnt = {
	.type = FS_LITTLEFS,
	.fs_data = &large,
	.storage_dev = (void *)FLASH_AREA_ID(large),
	.mnt_point = TESTFS_MNT_POINT_LARGE,
};

#endif /* CONFIG_APP_TEST_CUSTOM */

int testfs_lfs_wipe_partition(const struct fs_mount_t *mp)
{
	unsigned int id = (uintptr_t)mp->storage_dev;
	const struct flash_area *pfa;
	int rc = flash_area_open(id, &pfa);

	if (rc < 0) {
		TC_PRINT("Error accessing flash area %u [%d]\n",
			 id, rc);
		return TC_FAIL;
	}

	TC_PRINT("Erasing %zu (0x%zx) bytes\n", pfa->fa_size, pfa->fa_size);
	rc = flash_area_erase(pfa, 0, pfa->fa_size);
	(void)flash_area_close(pfa);

	if (rc < 0) {
		TC_PRINT("Error wiping flash area %u [%d]\n",
			 id, rc);
		return TC_FAIL;
	}

	TC_PRINT("Wiped flash area %u for %s\n", id, mp->mnt_point);
	return TC_PASS;
}
```

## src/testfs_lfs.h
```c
/*
 * Copyright (c) 2019 Peter Bigot Consulting, LLC
 *
 * SPDX-License-Identifier: Apache-2.0
 */

#ifndef _ZEPHYR_TESTS_SUBSYS_FS_LITTLEFS_TESTFS_LFS_H_
#define _ZEPHYR_TESTS_SUBSYS_FS_LITTLEFS_TESTFS_LFS_H_

#include <fs/fs.h>
#include "testfs_util.h"

#define TESTFS_MNT_POINT_SMALL "/sml"
#define TESTFS_MNT_POINT_MEDIUM "/med"
#define TESTFS_MNT_POINT_LARGE "/lrg"

extern struct fs_mount_t testfs_small_mnt;
extern struct fs_mount_t testfs_medium_mnt;
extern struct fs_mount_t testfs_large_mnt;

#define MEDIUM_IO_SIZE 64
#define MEDIUM_CACHE_SIZE 256
#define MEDIUM_LOOKAHEAD_SIZE 64

#define LARGE_IO_SIZE 256
#define LARGE_CACHE_SIZE 1024
#define LARGE_LOOKAHEAD_SIZE 128

/** Wipe all data from the flash partition associated with the given
 * mount point.
 *
 * This will cause it to be reformatted the next time it is mounted.
 *
 * @param mp pointer to the mount point data.  The flash partition ID
 * must be encoded in the fs_mount_t::storage_dev pointer.
 *
 * @return a standard test result code.
 */
int testfs_lfs_wipe_partition(const struct fs_mount_t *mp);

#endif /* _ZEPHYR_TESTS_SUBSYS_FS_LITTLEFS_TESTFS_LFS_H_ */
```

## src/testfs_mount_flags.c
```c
/*
 * Copyright (c) 2020 Nordic Semiconductor ASA
 *
 * SPDX-License-Identifier: Apache-2.0
 */

#include <ztest.h>
#include <fs/littlefs.h>
#include "testfs_tests.h"
#include "testfs_lfs.h"

static void cleanup(struct fs_mount_t *mp)
{
	TC_PRINT("Clean %s\n", mp->mnt_point);

	zassert_equal(testfs_lfs_wipe_partition(mp), TC_PASS,
		      "Failed to clean partition");
}

void test_fs_mount_flags(void)
{
	/* Using smallest partition for this tests as they do not write
	 * a lot of data, basically they just check flags.
	 */
	struct fs_mount_t *mp = &testfs_small_mnt;
	int ret = 0;
	struct fs_file_t fs;

	fs_file_t_init(&fs);
	cleanup(mp);

	/* Test FS_MOUNT_FLAG_NO_FORMAT flag */
	mp->flags |= FS_MOUNT_FLAG_NO_FORMAT;
	ret = fs_mount(mp);
	TC_PRINT("Mount unformatted with FS_MOUNT_FLAG_NO_FORMAT set\n");
	zassert_false(ret == 0, "Expected failure", ret);

	/* Test FS_MOUNT_FLAG_READ_ONLY on non-formatted volume*/
	mp->flags = FS_MOUNT_FLAG_READ_ONLY;
	ret = fs_mount(mp);
	TC_PRINT("Mount unformatted with FS_MOUNT_FLAG_READ_ONLY set\n");
	zassert_false(ret == 0, "Expected failure", ret);

	/* Format volume and add some files/dirs to check read-only flag */
	mp->flags = 0;
	ret = fs_mount(mp);
	TC_PRINT("Mount again to format volume\n");
	zassert_equal(ret, 0, "Expected success", ret);
	TC_PRINT("Create some file\n");
	ret = fs_open(&fs, "/sml/some", FS_O_CREATE);
	zassert_equal(ret, 0, "Expected success", ret);
	fs_close(&fs);
	TC_PRINT("Create other directory\n");
	ret = fs_mkdir("/sml/other");
	zassert_equal(ret, 0, "Expected success", ret);

	ret = fs_unmount(mp);
	zassert_equal(ret, 0, "Expected success", ret);

	/* Check fs operation on volume mounted with FS_MOUNT_FLAG_READ_ONLY */
	mp->flags = FS_MOUNT_FLAG_READ_ONLY;
	TC_PRINT("Mount as read-only\n");
	ret = fs_mount(mp);
	zassert_equal(ret, 0, "Expected success", ret);

	/* Attempt creating new file */
	ret = fs_open(&fs, "/sml/nosome", FS_O_CREATE);
	zassert_equal(ret, -EROFS, "Expected EROFS", ret);
	ret = fs_mkdir("/sml/another");
	zassert_equal(ret, -EROFS, "Expected EROFS", ret);
	ret = fs_rename("/sml/some", "/sml/nosome");
	zassert_equal(ret, -EROFS, "Expected EROFS", ret);
	ret = fs_unlink("/sml/some");
	zassert_equal(ret, -EROFS, "Expected EROFS", ret);
	ret = fs_open(&fs, "/sml/other", FS_O_CREATE);
	zassert_equal(ret, -EROFS, "Expected EROFS", ret);
	ret = fs_open(&fs, "/sml/some", FS_O_RDWR);
	zassert_equal(ret, -EROFS, "Expected EROFS", ret);
	ret = fs_open(&fs, "/sml/some", FS_O_READ);
	zassert_equal(ret, 0, "Expected success", ret);
	fs_close(&fs);
	ret = fs_unmount(mp);
	zassert_equal(ret, 0, "Expected success", ret);
}
```

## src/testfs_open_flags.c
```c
/*
 * Copyright (c) 2020 Nordic Semiconductor ASA
 *
 * SPDX-License-Identifier: Apache-2.0
 */

#include <ztest.h>
#include <fs/littlefs.h>
#include "testfs_tests.h"
#include "testfs_lfs.h"

void test_fs_open_flags(void);
/* Expected by test_fs_open_flags() */
const char *test_fs_open_flags_file_path = TESTFS_MNT_POINT_SMALL"/the_file";

static void mount(struct fs_mount_t *mp)
{
	TC_PRINT("Mount %s\n", mp->mnt_point);

	zassert_equal(fs_mount(mp), 0, "Failed to mount partition");
}

static void unmount(struct fs_mount_t *mp)
{
	TC_PRINT("Unmounting %s\n", mp->mnt_point);

	zassert_equal(fs_unmount(mp), 0,
		      "Failed to unmount partition");
}

static void cleanup(struct fs_mount_t *mp)
{
	TC_PRINT("Clean %s\n", mp->mnt_point);

	zassert_equal(testfs_lfs_wipe_partition(mp), TC_PASS,
		      "Failed to clean partition");
}

void test_fs_open_flags_lfs(void)
{
	/* Using smallest partition for this tests as they do not write
	 * a lot of data, basically they just check flags.
	 */
	struct fs_mount_t *mp = &testfs_small_mnt;

	cleanup(mp);
	mount(mp);

	test_fs_open_flags();

	unmount(mp);

}
```

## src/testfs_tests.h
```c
/*
 * Copyright (c) 2019 Peter Bigot Consulting, LLC
 *
 * SPDX-License-Identifier: Apache-2.0
 */

#ifndef _ZEPHYR_TESTS_SUBSYS_FS_LITTLEFS_TESTFS_TESTS_H_
#define  _ZEPHYR_TESTS_SUBSYS_FS_LITTLEFS_TESTFS_TESTS_H_

/* Tests in test_util */
void test_util_path_init_base(void);
void test_util_path_init_overrun(void);
void test_util_path_init_extended(void);
void test_util_path_extend(void);
void test_util_path_extend_up(void);
void test_util_path_extend_overrun(void);

/* Tests in test_lfs_basic */
void test_lfs_basic(void);

/* Tests in test_lfs_dirops */
void test_lfs_dirops(void);

/* Tests in test_lfs_perf */
void test_lfs_perf(void);

/* Test fs_open flags */
void test_fs_open_flags_lfs(void);

/* Test fs_mount flags */
void test_fs_mount_flags(void);

#endif /* _ZEPHYR_TESTS_SUBSYS_FS_LITTLEFS_TESTFS_TESTS_H_ */
```
